# ing920 register map
Vendor: INGChips; Series: ing920xx; File version: 1.0
CPU: CM3 r2p1, little endian, no MPU, no FPU, 2 interrupt priority bits
Registers are 32-bit, read-write, reset 0x0 unless marked. A register's access mark holds for its fields unless they carry their own. Offsets are from the block's base; [hi:lo] are bit positions.

## I2S
Base 0x40010000
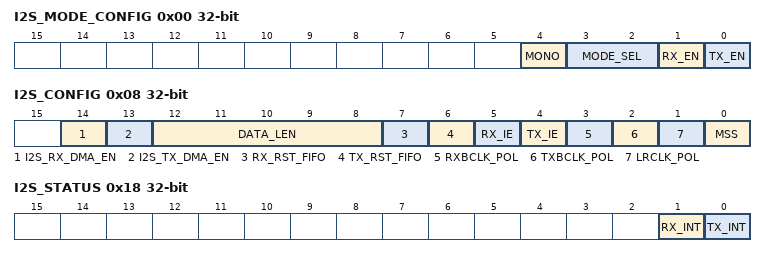
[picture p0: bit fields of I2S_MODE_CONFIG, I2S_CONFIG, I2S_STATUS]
0x00 I2S_MODE_CONFIG — reg description:
  [4] MONO — reg description:
  [3:2] MODE_SEL — reg description:
  [1] RX_EN — reg description:
  [0] TX_EN — reg description:
0x04 I2S_CLK_DIV — reg description:
  [6:0] LRDIV
0x08 I2S_CONFIG — reg description:
  [14] I2S_RX_DMA_EN — reg description:
  [13] I2S_TX_DMA_EN — reg description:
  [12:8] DATA_LEN — reg description:
  [7] RX_RST_FIFO — reg description:
  [6] TX_RST_FIFO — reg description:
  [5] RX_IE — reg description:
  [4] TX_IE — reg description:
  [3] RXBCLK_POL — reg description:
  [2] TXBCLK_POL — reg description:
  [1] LRCLK_POL — reg description:
  [0] MSS — reg description:
0x0C I2S_TX — reg description:
0x10 I2S_RX — reg description:
0x14 I2S_TRIG — reg description:
  [3:0] TX_TRIG
0x18 I2S_STATUS — reg description:
  [1] RX_INT — reg description:
  [0] TX_INT — reg description:
0x1C I2S_FIFO_STATUS — reg description:
  [4:0] TX_FIFO_CNT

## UART0
Base 0x40011000
Same registers: UART1 0x40012000
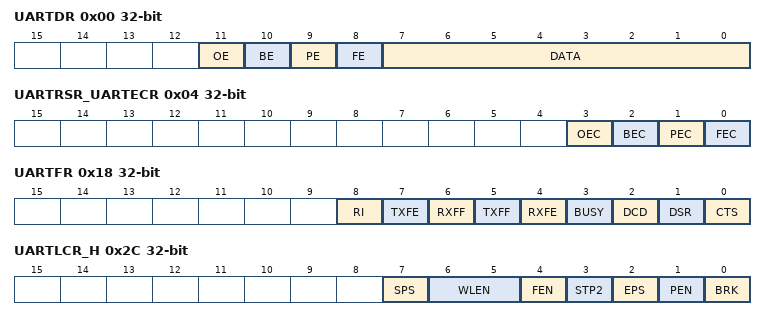
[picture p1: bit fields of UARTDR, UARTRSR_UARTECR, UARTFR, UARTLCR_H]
0x00 UARTDR — reg description:
  [11] OE — reg description:
  [10] BE — reg description:
  [9] PE — reg description:
  [8] FE — reg description:
  [7:0] DATA — reg description:
0x04 UARTRSR_UARTECR — reg description:
  [3] OEC — reg description:
  [2] BEC — reg description:
  [1] PEC — reg description:
  [0] FEC — reg description:
0x18 UARTFR — reg description:
  [8] RI — reg description:
  [7] TXFE — reg description:
  [6] RXFF — reg description:
  [5] TXFF — reg description:
  [4] RXFE — reg description:
  [3] BUSY — reg description:
  [2] DCD — reg description:
  [1] DSR — reg description:
  [0] CTS — reg description:
0x20 UARTILPR — reg description:
  [7:0] ILPDVSR
0x24 UARTIBRD — reg description:
  [15:0] BAUD_DIVINT
0x28 UARTFBRD — reg description:
  [5:0] BAUD_DIVFRAC
0x2C UARTLCR_H — reg description:
  [7] SPS — reg description:
  [6:5] WLEN — reg description:
  [4] FEN — reg description:
  [3] STP2 — reg description:
  [2] EPS — reg description:
  [1] PEN — reg description:
  [0] BRK — reg description:
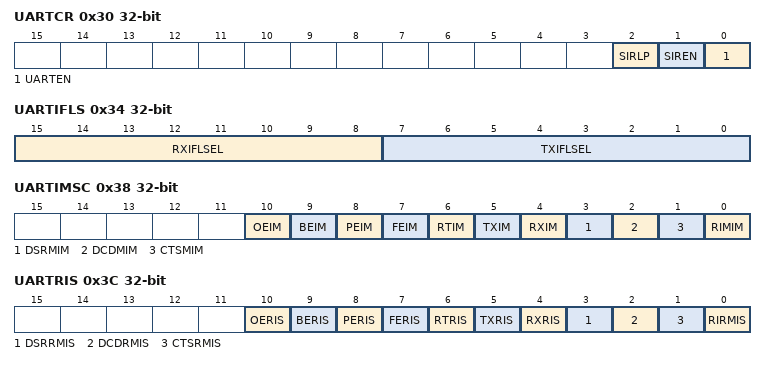
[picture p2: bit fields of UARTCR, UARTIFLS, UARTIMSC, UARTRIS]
0x30 UARTCR — reg description:
  [2] SIRLP — reg description:
  [1] SIREN — reg description:
  [0] UARTEN — reg description:
0x34 UARTIFLS — reg description:
  [15:8] RXIFLSEL — reg description:
  [7:0] TXIFLSEL — reg description:
0x38 UARTIMSC — reg description:
  [10] OEIM — reg description:
  [9] BEIM — reg description:
  [8] PEIM — reg description:
  [7] FEIM — reg description:
  [6] RTIM — reg description:
  [5] TXIM — reg description:
  [4] RXIM — reg description:
  [3] DSRMIM — reg description:
  [2] DCDMIM — reg description:
  [1] CTSMIM — reg description:
  [0] RIMIM — reg description:
0x3C UARTRIS — reg description:
  [10] OERIS — reg description:
  [9] BERIS — reg description:
  [8] PERIS — reg description:
  [7] FERIS — reg description:
  [6] RTRIS — reg description:
  [5] TXRIS — reg description:
  [4] RXRIS — reg description:
  [3] DSRRMIS — reg description:
  [2] DCDRMIS — reg description:
  [1] CTSRMIS — reg description:
  [0] RIRMIS — reg description:
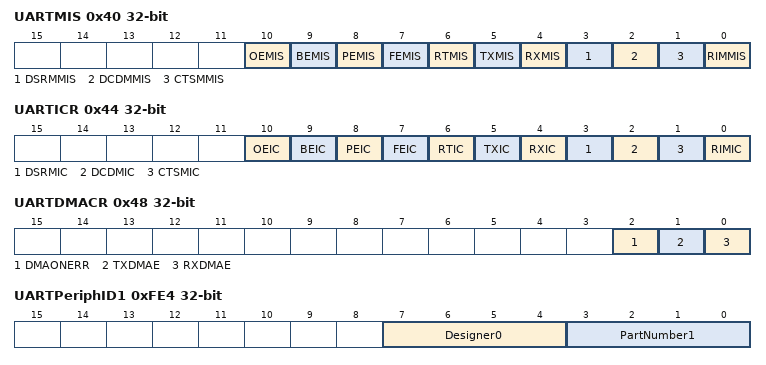
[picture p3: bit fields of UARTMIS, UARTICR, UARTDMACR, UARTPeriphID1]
0x40 UARTMIS — reg description:
  [10] OEMIS — reg description:
  [9] BEMIS — reg description:
  [8] PEMIS — reg description:
  [7] FEMIS — reg description:
  [6] RTMIS — reg description:
  [5] TXMIS — reg description:
  [4] RXMIS — reg description:
  [3] DSRMMIS — reg description:
  [2] DCDMMIS — reg description:
  [1] CTSMMIS — reg description:
  [0] RIMMIS — reg description:
0x44 UARTICR — reg description:
  [10] OEIC — reg description:
  [9] BEIC — reg description:
  [8] PEIC — reg description:
  [7] FEIC — reg description:
  [6] RTIC — reg description:
  [5] TXIC — reg description:
  [4] RXIC — reg description:
  [3] DSRMIC — reg description:
  [2] DCDMIC — reg description:
  [1] CTSMIC — reg description:
  [0] RIMIC — reg description:
0x48 UARTDMACR — reg description:
  [2] DMAONERR — reg description:
  [1] TXDMAE — reg description:
  [0] RXDMAE — reg description:
0xFE0 UARTPeriphID0 — reg description:
  [7:0] PartNumber0
0xFE4 UARTPeriphID1 — reg description:
  [7:4] Designer0 — reg description:
  [3:0] PartNumber1 — reg description:
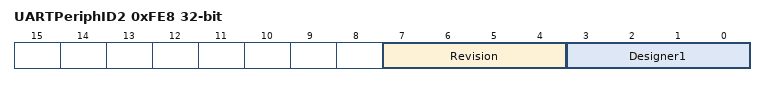
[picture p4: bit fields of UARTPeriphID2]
0xFE8 UARTPeriphID2 — reg description:
  [7:4] Revision — reg description:
  [3:0] Designer1 — reg description:
0xFEC UARTPeriphID3 — reg description:
  [7:0] Configuration
0xFF0 UARTPCellID0 — reg description:
  [7:0] UARTPCellID0
0xFF4 UARTPCellID1 — reg description:
  [7:0] UARTPCellID1
0xFF8 UARTPCellD2 — reg description:
  [7:0] UARTPCellID2
0xFFC UARTPCellID3 — reg description:
  [7:0] UARTPCellID3
